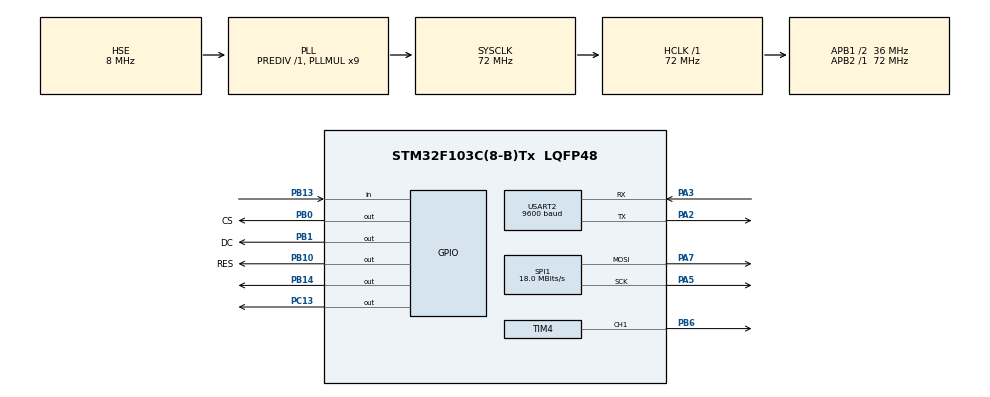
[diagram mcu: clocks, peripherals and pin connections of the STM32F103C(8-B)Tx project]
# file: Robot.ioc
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Dma.Request0=USART2_RX
Dma.USART2_RX.0.Direction=DMA_PERIPH_TO_MEMORY
Dma.USART2_RX.0.Instance=DMA1_Channel6
Dma.USART2_RX.0.MemDataAlignment=DMA_MDATAALIGN_BYTE
Dma.USART2_RX.0.MemInc=DMA_MINC_ENABLE
Dma.USART2_RX.0.Mode=DMA_NORMAL
Dma.USART2_RX.0.PeriphDataAlignment=DMA_PDATAALIGN_BYTE
Dma.USART2_RX.0.PeriphInc=DMA_PINC_DISABLE
Dma.USART2_RX.0.Priority=DMA_PRIORITY_VERY_HIGH
Mcu.Family=STM32F1
Mcu.Name=STM32F103C(8-B)Tx
Mcu.Package=LQFP48
NVIC.DMA1_Channel6_IRQn=true\:0\:0\:false\:false\:true\:false
NVIC.PriorityGroup=NVIC_PRIORITYGROUP_4
NVIC.TIM4_IRQn=true\:0\:0\:false\:false\:true\:true
NVIC.USART2_IRQn=true\:0\:0\:false\:false\:true\:true
PA13.Mode=Serial_Wire
PA13.Signal=SYS_JTMS-SWDIO
PA14.Mode=Serial_Wire
PA14.Signal=SYS_JTCK-SWCLK
PA2.Mode=Asynchronous
PA2.Signal=USART2_TX
PA3.Mode=Asynchronous
PA3.Signal=USART2_RX
PA5.Mode=TX_Only_Simplex_Unidirect_Master
PA5.Signal=SPI1_SCK
PA7.Mode=TX_Only_Simplex_Unidirect_Master
PA7.Signal=SPI1_MOSI
PB0.GPIO_Label=CS
PB0.GPIO_Speed=GPIO_SPEED_FREQ_HIGH
PB0.Signal=GPIO_Output
PB1.GPIO_Label=DC
PB1.GPIO_Speed=GPIO_SPEED_FREQ_HIGH
PB1.Signal=GPIO_Output
PB10.GPIO_Label=RES
PB10.GPIO_Speed=GPIO_SPEED_FREQ_HIGH
PB10.Signal=GPIO_Output
PB13.Signal=GPIO_Input
PB14.Signal=GPIO_Output
PB6.Signal=S_TIM4_CH1
PC13-TAMPER-RTC.GPIO_Speed=GPIO_SPEED_FREQ_HIGH
PC13-TAMPER-RTC.Signal=GPIO_Output
PD0-OSC_IN.Mode=HSE-External-Oscillator
PD0-OSC_IN.Signal=RCC_OSC_IN
PD1-OSC_OUT.Mode=HSE-External-Oscillator
PD1-OSC_OUT.Signal=RCC_OSC_OUT
ProjectManager.HeapSize=0x200
ProjectManager.StackSize=0x400
ProjectManager.TargetToolchain=SW4STM32
RCC.AHBFreq_Value=72000000
RCC.APB1CLKDivider=RCC_HCLK_DIV2
RCC.APB1Freq_Value=36000000
RCC.APB1TimFreq_Value=72000000
RCC.APB2Freq_Value=72000000
RCC.APB2TimFreq_Value=72000000
RCC.HCLKFreq_Value=72000000
RCC.PLLMUL=RCC_PLL_MUL9
RCC.PLLSourceVirtual=RCC_PLLSOURCE_HSE
RCC.SYSCLKFreq_VALUE=72000000
RCC.SYSCLKSource=RCC_SYSCLKSOURCE_PLLCLK
RCC.USBFreq_Value=72000000
SH.S_TIM4_CH1.0=TIM4_CH1,PWM Generation1 CH1
SPI1.BaudRatePrescaler=SPI_BAUDRATEPRESCALER_4
SPI1.CLKPhase=SPI_PHASE_2EDGE
SPI1.CLKPolarity=SPI_POLARITY_HIGH
SPI1.CalculateBaudRate=18.0 MBits/s
SPI1.Direction=SPI_DIRECTION_2LINES
SPI1.Mode=SPI_MODE_MASTER
SPI1.VirtualType=VM_MASTER
TIM1.Period=65534
TIM1.Prescaler=71
TIM4.Channel-PWM\ Generation1\ CH1=TIM_CHANNEL_1
TIM4.Period=999
TIM4.Prescaler=1439
USART2.BaudRate=9600
USART2.VirtualMode=VM_ASYNC
VP_TIM1_VS_ClockSourceINT.Mode=Internal
VP_TIM4_VS_ClockSourceINT.Mode=Internal
board=custom

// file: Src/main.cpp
/* USER CODE BEGIN Header */
/**
 ******************************************************************************
 * @file           : main.c
 * @brief          : Main program body
 ******************************************************************************
 ** This notice applies to any and all portions of this file
 * that are not between comment pairs USER CODE BEGIN and
 * USER CODE END. Other portions of this file, whether
 * inserted by the user or by software development tools
 * are owned by their respective copyright owners.
 *
 * COPYRIGHT(c) 2019 STMicroelectronics
 *
 * Redistribution and use in source and binary forms, with or without modification,
 * are permitted provided that the following conditions are met:
 *   1. Redistributions of source code must retain the above copyright notice,
 *      this list of conditions and the following disclaimer.
 *   2. Redistributions in binary form must reproduce the above copyright notice,
 *      this list of conditions and the following disclaimer in the documentation
 *      and/or other materials provided with the distribution.
 *   3. Neither the name of STMicroelectronics nor the names of its contributors
 *      may be used to endorse or promote products derived from this software
 *      without specific prior written permission.
 *
 * THIS SOFTWARE IS PROVIDED BY THE COPYRIGHT HOLDERS AND CONTRIBUTORS "AS IS"
 * AND ANY EXPRESS OR IMPLIED WARRANTIES, INCLUDING, BUT NOT LIMITED TO, THE
 * IMPLIED WARRANTIES OF MERCHANTABILITY AND FITNESS FOR A PARTICULAR PURPOSE ARE
 * DISCLAIMED. IN NO EVENT SHALL THE COPYRIGHT HOLDER OR CONTRIBUTORS BE LIABLE
 * FOR ANY DIRECT, INDIRECT, INCIDENTAL, SPECIAL, EXEMPLARY, OR CONSEQUENTIAL
 * DAMAGES (INCLUDING, BUT NOT LIMITED TO, PROCUREMENT OF SUBSTITUTE GOODS OR
 * SERVICES; LOSS OF USE, DATA, OR PROFITS; OR BUSINESS INTERRUPTION) HOWEVER
 * CAUSED AND ON ANY THEORY OF LIABILITY, WHETHER IN CONTRACT, STRICT LIABILITY,
 * OR TORT (INCLUDING NEGLIGENCE OR OTHERWISE) ARISING IN ANY WAY OUT OF THE USE
 * OF THIS SOFTWARE, EVEN IF ADVISED OF THE POSSIBILITY OF SUCH DAMAGE.
 *
 ******************************************************************************
 */
/* USER CODE END Header */

#include "main.h"
#include "usart.h"
#include "tim.h"
#include "gpio.h"
#include "dma.h"
#include "spi.h"
#include "../Core/DataHandler.h"
#include "../Core/Servo.h"
#include "../Core/Sonar.h"

void SystemClock_Config(void);

int main(void) {

	/* MCU Configuration--------------------------------------------------------*/

	/* Reset of all peripherals, Initializes the Flash interface and the Systick. */
	HAL_Init();

	/* Configure the system clock */
	SystemClock_Config();

	/* Initialize all configured peripherals */
	MX_GPIO_Init();
	MX_DMA_Init();
	MX_USART2_UART_Init();
	MX_TIM4_Init();
	MX_TIM1_Init();
	MX_SPI1_Init();
	/* USER CODE BEGIN 2 */
	DataHandler *instance = DataHandler::getInstace();
	instance->resetEsp();
	HAL_Delay(10000);
	instance->espStart();
	instance->testEsp();
	instance->getIp();
	instance->getIpInfo();
	instance->createUDPServer();
	/* USER CODE END 2 */
	/* Infinite loop */
	/* USER CODE BEGIN WHILE */
//	Sonar sonar;
	while (1) {
//		if(__HAL_TIM_GET_COUNTER(&htim1) == 10)
//		{
////			HAL_GPIO_WritePin(GPIOB, GPIO_PIN_13, GPIO_PIN_SET);
		HAL_GPIO_TogglePin(GPIOB, GPIO_PIN_13);
//			__HAL_TIM_SET_COUNTER(&htim1, 0);
//		}
		HAL_Delay(100);
//		HAL_GPIO_TogglePin(GPIOC, GPIO_PIN_13);
		/* USER CODE END WHILE */
	}
}

void SystemClock_Config(void) {
	RCC_OscInitTypeDef RCC_OscInitStruct = { 0 };
	RCC_ClkInitTypeDef RCC_ClkInitStruct = { 0 };

	/**Initializes the CPU, AHB and APB busses clocks
	 */
	RCC_OscInitStruct.OscillatorType = RCC_OSCILLATORTYPE_HSE;
	RCC_OscInitStruct.HSEState = RCC_HSE_ON;
	RCC_OscInitStruct.HSEPredivValue = RCC_HSE_PREDIV_DIV1;
	RCC_OscInitStruct.HSIState = RCC_HSI_ON;
	RCC_OscInitStruct.PLL.PLLState = RCC_PLL_ON;
	RCC_OscInitStruct.PLL.PLLSource = RCC_PLLSOURCE_HSE;
	RCC_OscInitStruct.PLL.PLLMUL = RCC_PLL_MUL9;
	if (HAL_RCC_OscConfig(&RCC_OscInitStruct) != HAL_OK) {
		Error_Handler();
	}
	/**Initializes the CPU, AHB and APB busses clocks
	 */
	RCC_ClkInitStruct.ClockType = RCC_CLOCKTYPE_HCLK | RCC_CLOCKTYPE_SYSCLK
			| RCC_CLOCKTYPE_PCLK1 | RCC_CLOCKTYPE_PCLK2;
	RCC_ClkInitStruct.SYSCLKSource = RCC_SYSCLKSOURCE_PLLCLK;
	RCC_ClkInitStruct.AHBCLKDivider = RCC_SYSCLK_DIV1;
	RCC_ClkInitStruct.APB1CLKDivider = RCC_HCLK_DIV2;
	RCC_ClkInitStruct.APB2CLKDivider = RCC_HCLK_DIV1;

	if (HAL_RCC_ClockConfig(&RCC_ClkInitStruct, FLASH_LATENCY_2) != HAL_OK) {
		Error_Handler();
	}
}

void Error_Handler(void) {
}

/************************ (C) COPYRIGHT STMicroelectronics *****END OF FILE****/
